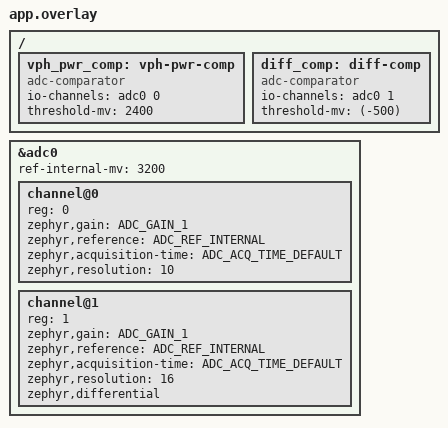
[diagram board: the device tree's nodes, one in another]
/*
 * Copyright 2026 Google LLC
 *
 * SPDX-License-Identifier: Apache-2.0
 */

/ {
	vph_pwr_comp: vph-pwr-comp {
		compatible = "adc-comparator";
		io-channels = <&adc0 0>;
		threshold-mv = <2400>;
	};

	diff_comp: diff-comp {
		compatible = "adc-comparator";
		io-channels = <&adc0 1>;
		threshold-mv = <(-500)>;
	};
};

&adc0 {
	ref-internal-mv = <3200>;
	#address-cells = <1>;
	#size-cells = <0>;

	channel@0 {
		reg = <0>;
		zephyr,gain = "ADC_GAIN_1";
		zephyr,reference = "ADC_REF_INTERNAL";
		zephyr,acquisition-time = <ADC_ACQ_TIME_DEFAULT>;
		zephyr,resolution = <10>;
	};

	channel@1 {
		reg = <1>;
		zephyr,gain = "ADC_GAIN_1";
		zephyr,reference = "ADC_REF_INTERNAL";
		zephyr,acquisition-time = <ADC_ACQ_TIME_DEFAULT>;
		zephyr,resolution = <16>;
		zephyr,differential;
	};
};
